# ioam3358 register map
Registers are 32-bit, access not given, no defined reset value unless marked. A register's access mark holds for its fields unless they carry their own. Addresses are absolute; registers are grouped by the start of their names; [hi:lo] are bit positions; {n}, {i} and the like mark numbered series; 'fields as' and 'values as' point back to an identical list.

## WDT1
0x44E35000 WDT1_WIDR
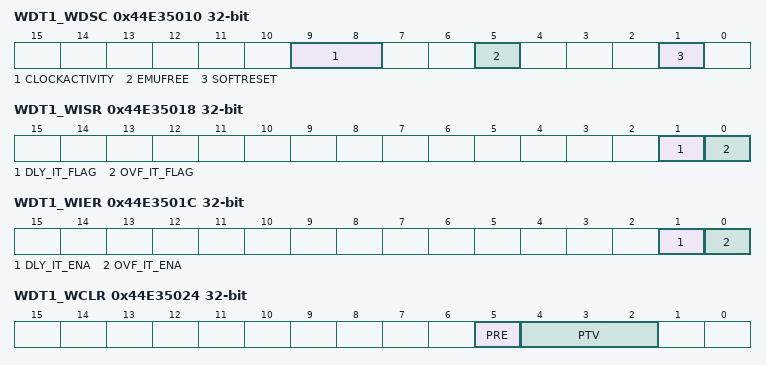
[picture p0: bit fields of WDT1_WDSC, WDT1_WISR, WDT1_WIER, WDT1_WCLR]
0x44E35010 WDT1_WDSC
  [9:8] CLOCKACTIVITY, [5] EMUFREE, [1] SOFTRESET
0x44E35014 WDT1_WDST
  [0] RESETDONE
0x44E35018 WDT1_WISR
  [1] DLY_IT_FLAG, [0] OVF_IT_FLAG
0x44E3501C WDT1_WIER
  [1] DLY_IT_ENA, [0] OVF_IT_ENA
0x44E35024 WDT1_WCLR
  [5] PRE, [4:2] PTV
0x44E35028 WDT1_WCRR
0x44E3502C WDT1_WLDR
0x44E35030 WDT1_WTGR
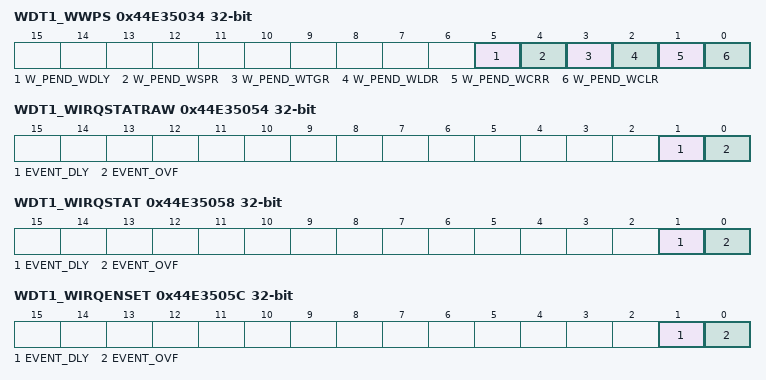
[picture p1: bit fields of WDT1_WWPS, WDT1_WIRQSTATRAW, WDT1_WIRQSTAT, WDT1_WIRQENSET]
0x44E35034 WDT1_WWPS
  [5] W_PEND_WDLY, [4] W_PEND_WSPR, [3] W_PEND_WTGR, [2] W_PEND_WLDR, [1] W_PEND_WCRR, [0] W_PEND_WCLR
0x44E35044 WDT1_WDLY
0x44E35048 WDT1_WSPR
0x44E35054 WDT1_WIRQSTATRAW
  [1] EVENT_DLY, [0] EVENT_OVF
0x44E35058 WDT1_WIRQSTAT
  [1] EVENT_DLY, [0] EVENT_OVF
0x44E3505C WDT1_WIRQENSET
  [1] EVENT_DLY, [0] EVENT_OVF
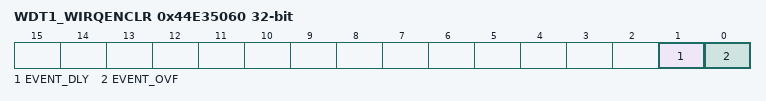
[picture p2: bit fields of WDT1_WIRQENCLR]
0x44E35060 WDT1_WIRQENCLR
  [1] EVENT_DLY, [0] EVENT_OVF

## I2C0
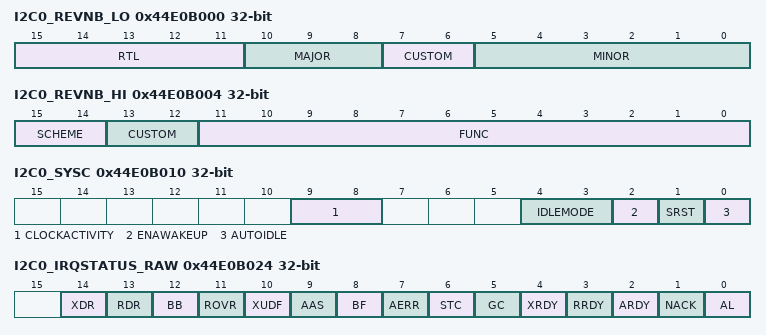
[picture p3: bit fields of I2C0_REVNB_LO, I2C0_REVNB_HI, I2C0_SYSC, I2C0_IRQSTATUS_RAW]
0x44E0B000 I2C0_REVNB_LO
  [15:11] RTL, [10:8] MAJOR, [7:6] CUSTOM, [5:0] MINOR
0x44E0B004 I2C0_REVNB_HI
  [15:14] SCHEME, [13:12] CUSTOM, [11:0] FUNC
0x44E0B010 I2C0_SYSC
  [9:8] CLOCKACTIVITY, [4:3] IDLEMODE, [2] ENAWAKEUP, [1] SRST, [0] AUTOIDLE
0x44E0B020 I2C0_EOI
  [0] LINE_NUMBER
0x44E0B024 I2C0_IRQSTATUS_RAW
  [14] XDR, [13] RDR, [12] BB, [11] ROVR, [10] XUDF, [9] AAS, [8] BF, [7] AERR, [6] STC, [5] GC, [4] XRDY, [3] RRDY, [2] ARDY, [1] NACK, [0] AL
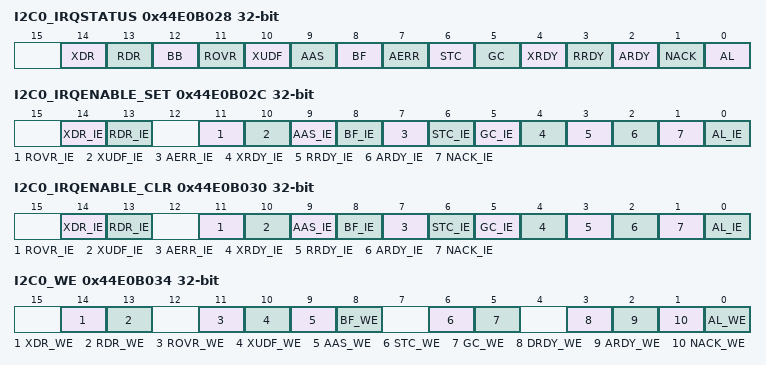
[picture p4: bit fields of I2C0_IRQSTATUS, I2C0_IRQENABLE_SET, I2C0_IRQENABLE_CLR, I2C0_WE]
0x44E0B028 I2C0_IRQSTATUS
  fields as I2C0_IRQSTATUS_RAW
0x44E0B02C I2C0_IRQENABLE_SET
  [14] XDR_IE, [13] RDR_IE, [11] ROVR_IE, [10] XUDF_IE, [9] AAS_IE, [8] BF_IE, [7] AERR_IE, [6] STC_IE, [5] GC_IE, [4] XRDY_IE, [3] RRDY_IE, [2] ARDY_IE, [1] NACK_IE, [0] AL_IE
0x44E0B030 I2C0_IRQENABLE_CLR
  fields as I2C0_IRQENABLE_SET
0x44E0B034 I2C0_WE
  [14] XDR_WE, [13] RDR_WE, [11] ROVR_WE, [10] XUDF_WE, [9] AAS_WE, [8] BF_WE, [6] STC_WE, [5] GC_WE, [3] DRDY_WE, [2] ARDY_WE, [1] NACK_WE, [0] AL_WE
0x44E0B038 I2C0_DMARXENABLE_SET
  [0] DMARX_ENABLE_SET
0x44E0B03C I2C0_DMATXENABLE_SET
  [0] DMATX_ENABLE_SET
0x44E0B040 I2C0_DMARXENABLE_CLR
  [0] DMARX_ENABLE_CLEAR
0x44E0B044 I2C0_DMATXENABLE_CLR
  [0] DMARX_ENABLE_CLEAR
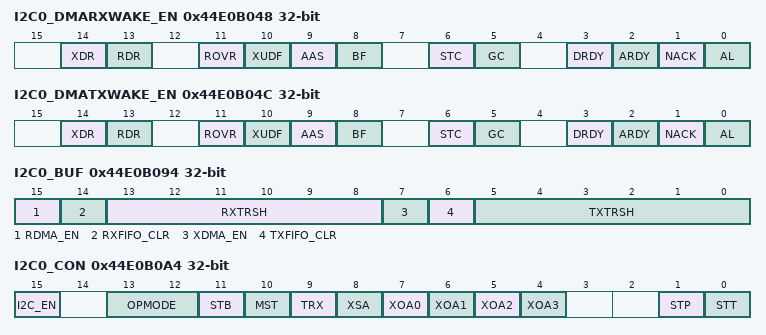
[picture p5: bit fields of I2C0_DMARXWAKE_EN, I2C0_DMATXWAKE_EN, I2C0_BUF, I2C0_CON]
0x44E0B048 I2C0_DMARXWAKE_EN
  [14] XDR, [13] RDR, [11] ROVR, [10] XUDF, [9] AAS, [8] BF, [6] STC, [5] GC, [3] DRDY, [2] ARDY, [1] NACK, [0] AL
0x44E0B04C I2C0_DMATXWAKE_EN
  fields as I2C0_DMARXWAKE_EN
0x44E0B090 I2C0_SYSS
  [0] RDONE
0x44E0B094 I2C0_BUF
  [15] RDMA_EN, [14] RXFIFO_CLR, [13:8] RXTRSH, [7] XDMA_EN, [6] TXFIFO_CLR, [5:0] TXTRSH
0x44E0B098 I2C0_CNT
  [15:0] DCOUNT
0x44E0B09C I2C0_DATA
  [7:0] DATA
0x44E0B0A4 I2C0_CON
  [15] I2C_EN, [13:12] OPMODE, [11] STB, [10] MST, [9] TRX, [8] XSA, [7-n] XOA{n} (n=0..3), [1] STP, [0] STT
0x44E0B0A8 I2C0_OA
  [9:0] OA
0x44E0B0AC I2C0_SA
  [9:0] SA
0x44E0B0B0 I2C0_PSC
  [7:0] PSC
0x44E0B0B4 I2C0_SCLL
  [7:0] SCLL
0x44E0B0B8 I2C0_SCLH
  [7:0] SCLH
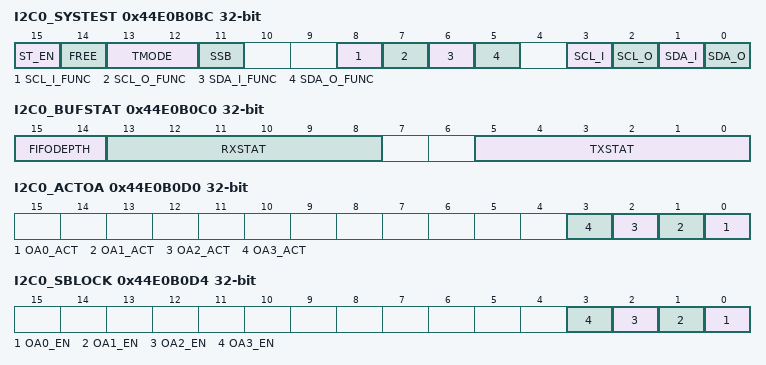
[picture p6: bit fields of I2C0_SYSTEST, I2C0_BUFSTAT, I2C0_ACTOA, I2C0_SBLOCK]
0x44E0B0BC I2C0_SYSTEST
  [15] ST_EN, [14] FREE, [13:12] TMODE, [11] SSB, [8] SCL_I_FUNC, [7] SCL_O_FUNC, [6] SDA_I_FUNC, [5] SDA_O_FUNC, [3] SCL_I, [2] SCL_O, [1] SDA_I, [0] SDA_O
0x44E0B0C0 I2C0_BUFSTAT
  [15:14] FIFODEPTH, [13:8] RXSTAT, [5:0] TXSTAT
{0x44E0B0C0+4i} I2C0_OA{i} (i=1..3)
  [9:0] OA{i}
0x44E0B0D0 I2C0_ACTOA
  [n] OA{n}_ACT (n=0..3)
0x44E0B0D4 I2C0_SBLOCK
  [n] OA{n}_EN (n=0..3)

## I2C1
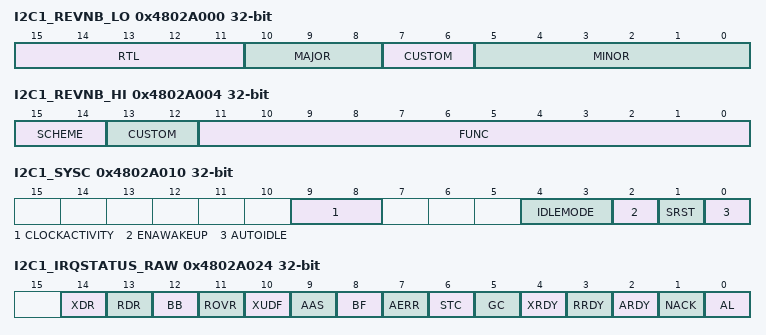
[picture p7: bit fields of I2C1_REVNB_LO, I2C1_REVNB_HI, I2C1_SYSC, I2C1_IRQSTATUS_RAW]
0x4802A000 I2C1_REVNB_LO
  [15:11] RTL, [10:8] MAJOR, [7:6] CUSTOM, [5:0] MINOR
0x4802A004 I2C1_REVNB_HI
  [15:14] SCHEME, [13:12] CUSTOM, [11:0] FUNC
0x4802A010 I2C1_SYSC
  [9:8] CLOCKACTIVITY, [4:3] IDLEMODE, [2] ENAWAKEUP, [1] SRST, [0] AUTOIDLE
0x4802A020 I2C1_EOI
  [0] LINE_NUMBER
0x4802A024 I2C1_IRQSTATUS_RAW
  [14] XDR, [13] RDR, [12] BB, [11] ROVR, [10] XUDF, [9] AAS, [8] BF, [7] AERR, [6] STC, [5] GC, [4] XRDY, [3] RRDY, [2] ARDY, [1] NACK, [0] AL
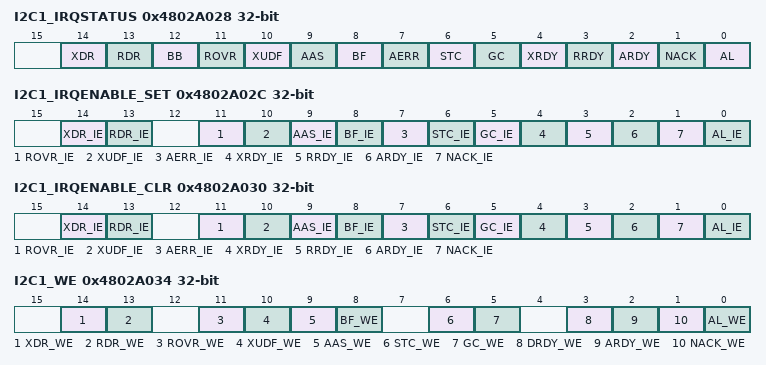
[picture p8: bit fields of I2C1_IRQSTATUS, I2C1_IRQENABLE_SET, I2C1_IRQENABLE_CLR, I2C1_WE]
0x4802A028 I2C1_IRQSTATUS
  fields as I2C1_IRQSTATUS_RAW
0x4802A02C I2C1_IRQENABLE_SET
  [14] XDR_IE, [13] RDR_IE, [11] ROVR_IE, [10] XUDF_IE, [9] AAS_IE, [8] BF_IE, [7] AERR_IE, [6] STC_IE, [5] GC_IE, [4] XRDY_IE, [3] RRDY_IE, [2] ARDY_IE, [1] NACK_IE, [0] AL_IE
0x4802A030 I2C1_IRQENABLE_CLR
  fields as I2C1_IRQENABLE_SET
0x4802A034 I2C1_WE
  [14] XDR_WE, [13] RDR_WE, [11] ROVR_WE, [10] XUDF_WE, [9] AAS_WE, [8] BF_WE, [6] STC_WE, [5] GC_WE, [3] DRDY_WE, [2] ARDY_WE, [1] NACK_WE, [0] AL_WE
0x4802A038 I2C1_DMARXENABLE_SET
  [0] DMARX_ENABLE_SET
0x4802A03C I2C1_DMATXENABLE_SET
  [0] DMATX_ENABLE_SET
0x4802A040 I2C1_DMARXENABLE_CLR
  [0] DMARX_ENABLE_CLEAR
0x4802A044 I2C1_DMATXENABLE_CLR
  [0] DMARX_ENABLE_CLEAR
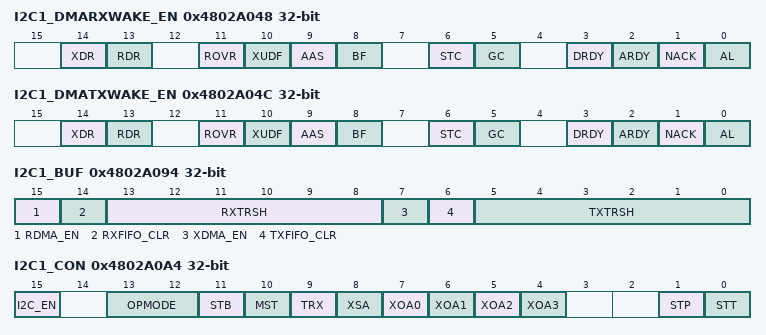
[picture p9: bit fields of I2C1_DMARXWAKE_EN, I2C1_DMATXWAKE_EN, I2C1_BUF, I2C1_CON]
0x4802A048 I2C1_DMARXWAKE_EN
  [14] XDR, [13] RDR, [11] ROVR, [10] XUDF, [9] AAS, [8] BF, [6] STC, [5] GC, [3] DRDY, [2] ARDY, [1] NACK, [0] AL
0x4802A04C I2C1_DMATXWAKE_EN
  fields as I2C1_DMARXWAKE_EN
0x4802A090 I2C1_SYSS
  [0] RDONE
0x4802A094 I2C1_BUF
  [15] RDMA_EN, [14] RXFIFO_CLR, [13:8] RXTRSH, [7] XDMA_EN, [6] TXFIFO_CLR, [5:0] TXTRSH
0x4802A098 I2C1_CNT
  [15:0] DCOUNT
0x4802A0A4 I2C1_CON
  [15] I2C_EN, [13:12] OPMODE, [11] STB, [10] MST, [9] TRX, [8] XSA, [7-n] XOA{n} (n=0..3), [1] STP, [0] STT
0x4802A0A8 I2C1_OA
  [9:0] OA
0x4802A0AC I2C1_SA
  [9:0] SA
0x4802A0B0 I2C1_PSC
  [7:0] PSC
0x4802A0B4 I2C1_SCLL
  [7:0] SCLL
0x4802A0B8 I2C1_SCLH
  [7:0] SCLH
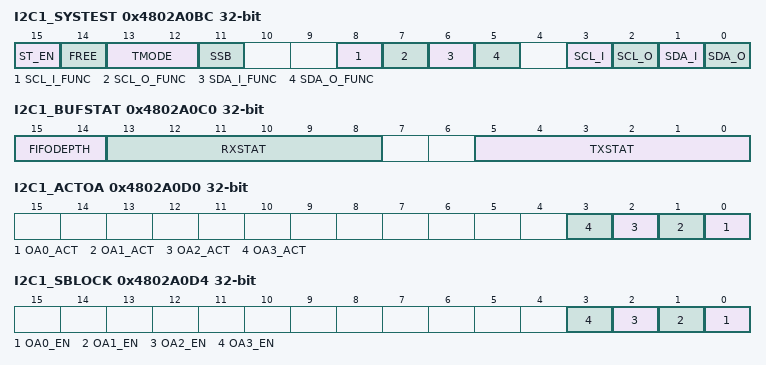
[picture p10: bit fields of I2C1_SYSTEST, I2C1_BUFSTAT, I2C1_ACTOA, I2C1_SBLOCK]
0x4802A0BC I2C1_SYSTEST
  [15] ST_EN, [14] FREE, [13:12] TMODE, [11] SSB, [8] SCL_I_FUNC, [7] SCL_O_FUNC, [6] SDA_I_FUNC, [5] SDA_O_FUNC, [3] SCL_I, [2] SCL_O, [1] SDA_I, [0] SDA_O
0x4802A0C0 I2C1_BUFSTAT
  [15:14] FIFODEPTH, [13:8] RXSTAT, [5:0] TXSTAT
{0x4802A0C0+4i} I2C1_OA{i} (i=1..3)
  [9:0] OA{i}
0x4802A0D0 I2C1_ACTOA
  [n] OA{n}_ACT (n=0..3)
0x4802A0D4 I2C1_SBLOCK
  [n] OA{n}_EN (n=0..3)
